# CH572SFR register map
Vendor: WCH Ltd.; Series: CH572; File version: 1.1
CPU: RISC-V r0p0, little endian, no MPU, no FPU, 2 interrupt priority bits
Registers are 32-bit, read-write, reset 0x0 unless marked. A register's access mark holds for its fields unless they carry their own. Offsets are from the block's base; [hi:lo] are bit positions; 'fields as' and 'values as' point back to an identical list.

## KEYSCAN — keys scanning
Base 0x40001000
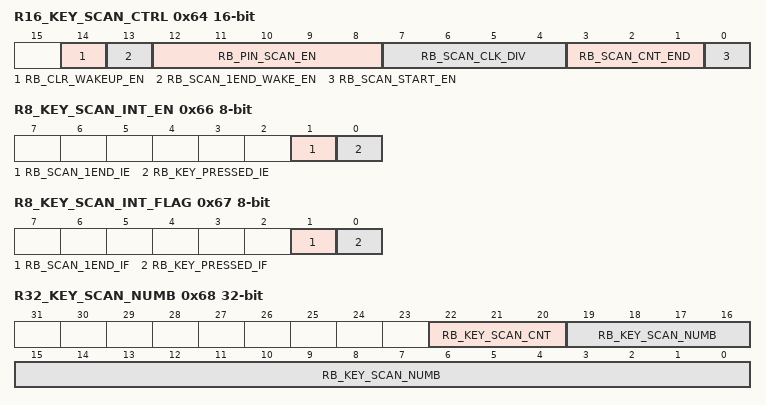
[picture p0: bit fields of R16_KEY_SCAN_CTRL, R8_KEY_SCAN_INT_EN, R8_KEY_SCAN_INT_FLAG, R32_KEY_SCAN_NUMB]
0x64 R16_KEY_SCAN_CTRL 16-bit — RW, Key scan control register
  [14] RB_CLR_WAKEUP_EN ro — RW, Enable automatic clearing of wake-up signal after wake-up
  [13] RB_SCAN_1END_WAKE_EN — RW, Activate wake-up signal after a single scan
  [12:8] RB_PIN_SCAN_EN — RW, Enable I/O pins involved in key scanning
  [7:4] RB_SCAN_CLK_DIV — RW, Scan clock frequency division
  [3:1] RB_SCAN_CNT_END — RW, Set the number of times to scan to the same key value
  [0] RB_SCAN_START_EN — RW, Start scanning enable
0x66 R8_KEY_SCAN_INT_EN 8-bit — RW, Press button scan interrupt enable register
  [1] RB_SCAN_1END_IE — RW, Interrupt enable after a single scan is completed
  [0] RB_KEY_PRESSED_IE — RW, Detected key press and interrupted when the same key value is reached the set value
0x67 R8_KEY_SCAN_INT_FLAG 8-bit — RW, Press the button to scan the interrupt flag register
  [1] RB_SCAN_1END_IF — RW, Interrupt flag after word scanning is completed
  [0] RB_KEY_PRESSED_IF — RW, Detected button press, and the same button value reaches the set value for the number of times interrupt flag
0x68 R32_KEY_SCAN_NUMB ro — RW, Scan key number register
  [22:20] RB_KEY_SCAN_CNT — RO, Current number of key scans
  [19:0] RB_KEY_SCAN_NUMB — RO, Current key number value

## KEYSCAN — keys scanning
Base 0x40001000
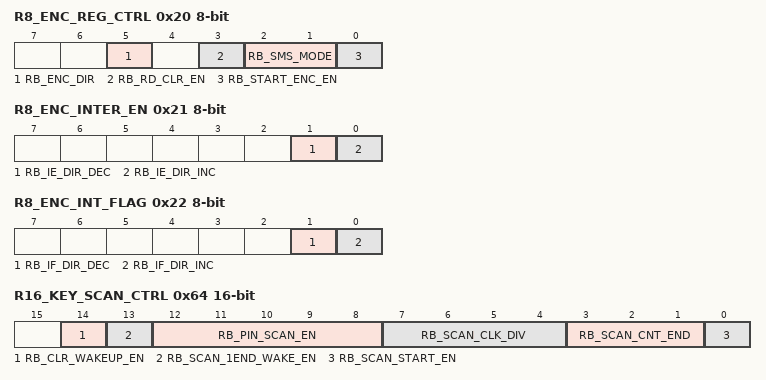
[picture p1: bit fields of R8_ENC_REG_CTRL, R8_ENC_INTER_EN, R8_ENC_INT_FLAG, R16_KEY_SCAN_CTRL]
0x20 R8_ENC_REG_CTRL 8-bit — RW, Encoder mode control register
  [5] RB_ENC_DIR ro — RO, Current direction of encoder
  [3] RB_RD_CLR_EN — RW, Encoder mode reads count and resets to zero
  [2:1] RB_SMS_MODE — RW, Encoder mode edge working mode
  [0] RB_START_ENC_EN — RW, Enable encoder mode operation
0x21 R8_ENC_INTER_EN 8-bit — RW, Encoder mode interrupt enable register
  [1] RB_IE_DIR_DEC — RW, Encoder mode backward interrupt enable
  [0] RB_IE_DIR_INC — RW, Encoder mode forward interrupt enable
0x22 R8_ENC_INT_FLAG 8-bit — RW, Encoder mode interrupt flag register
  [1] RB_IF_DIR_DEC — RW, Encoder mode backward interrupt flag
  [0] RB_IF_DIR_INC — RW, Encoder mode forward interrupt flag
0x24 R32_ENC_REG_CEND — RW, Encoder mode final value configuration register
  [31:0] R32_ENC_REG_CEND — RW, Preset encoder mode final value
0x28 R32_ENC_REG_CCNT ro — RW, Encoder mode current value configuration register
  [31:0] R32_ENC_REG_CCNT — RO, Current encoder mode value
0x64 R16_KEY_SCAN_CTRL 16-bit — RW, Key scan control register
  fields as R16_KEY_SCAN_CTRL
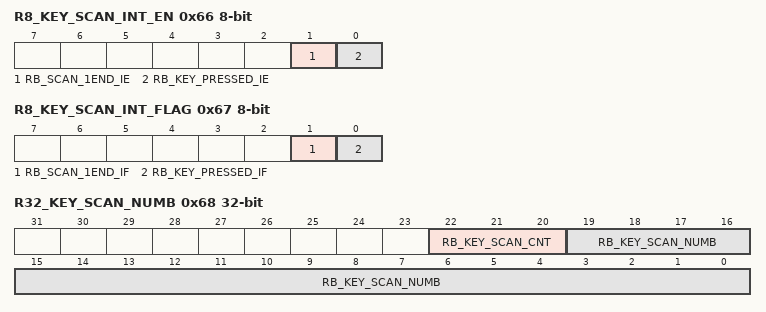
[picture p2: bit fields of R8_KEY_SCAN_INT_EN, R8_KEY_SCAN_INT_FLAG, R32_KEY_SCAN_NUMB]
0x66 R8_KEY_SCAN_INT_EN 8-bit — RW, Press button scan interrupt enable register
  fields as R8_KEY_SCAN_INT_EN
0x67 R8_KEY_SCAN_INT_FLAG 8-bit — RW, Press the button to scan the interrupt flag register
  fields as R8_KEY_SCAN_INT_FLAG
0x68 R32_KEY_SCAN_NUMB ro — RW, Scan key number register
  fields as R32_KEY_SCAN_NUMB

## GPIO — General porpose intput output
Base 0x40001000
0x90 R16_PA_INT_EN 16-bit — RW, GPIO PA interrupt enable
  [15:0] R16_PA_INT_EN — GPIO PA interrupt enable
0x94 R16_PA_INT_MODE 16-bit — RW, GPIO PA interrupt mode: 0=level action, 1=edge action
  [15:0] R16_PA_INT_MODE — GPIO PA interrupt mode
0x9C R16_PA_INT_IF 16-bit — RW1, GPIO PA interrupt flag
  [15:0] R16_PA_INT_IF — GPIO PA interrupt flag
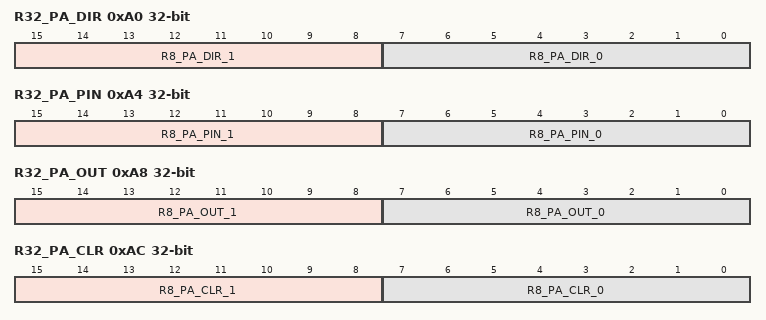
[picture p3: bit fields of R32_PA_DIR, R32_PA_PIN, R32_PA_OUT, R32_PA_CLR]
0xA0 R32_PA_DIR — RW, GPIO PA I/O direction: 0=in, 1=out
  [15:8] R8_PA_DIR_1 — GPIO PA I/O direction byte 1
  [7:0] R8_PA_DIR_0 — GPIO PA I/O direction byte 0
0xA4 R32_PA_PIN ro reset not defined — RO, GPIO PA input
  [15:8] R8_PA_PIN_1 — GPIO PA input byte 1
  [7:0] R8_PA_PIN_0 — GPIO PA input byte 0
0xA8 R32_PA_OUT — RW, GPIO PA output
  [15:8] R8_PA_OUT_1 — GPIO PA output byte 1
  [7:0] R8_PA_OUT_0 — GPIO PA output byte 0
0xAC R32_PA_CLR wo — WZ, GPIO PA clear output: 0=keep, 1=clear
  [15:8] R8_PA_CLR_1 — GPIO PA clear output byte 1
  [7:0] R8_PA_CLR_0 — GPIO PA clear output byte 0
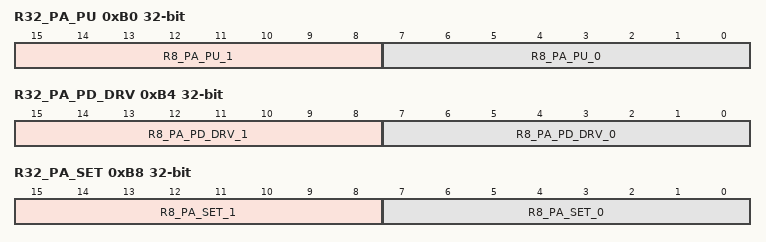
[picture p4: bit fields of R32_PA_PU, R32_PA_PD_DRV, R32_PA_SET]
0xB0 R32_PA_PU — RW, GPIO PA pullup resistance enable
  [15:8] R8_PA_PU_1 — GPIO PA pullup resistance enable byte 0
  [7:0] R8_PA_PU_0 — GPIO PA pullup resistance enable byte 0
0xB4 R32_PA_PD_DRV — RW, PA pulldown for input or PA driving capability for output
  [15:8] R8_PA_PD_DRV_1 — PA pulldown for input or PA driving capability for output byte 1
  [7:0] R8_PA_PD_DRV_0 — PA pulldown for input or PA driving capability for output byte 0
0xB8 R32_PA_SET — RW, PA port output set register
  [15:8] R8_PA_SET_1 — When the corresponding bit of the set register R3_2PA_SET is 0, the output of the PA pin remains unchanged; When it is 1, the PA pin outputs a high level
  [7:0] R8_PA_SET_0 — When the corresponding bit of the set register R3_2PA_SET is 0, the output of the PA pin remains unchanged; When it is 1, the PA pin outputs a high level
